# CH564 register map
Vendor: WCH Ltd.; File version: 1.0
Registers are 8-bit, read-write, reset 0x0 unless marked. A register's access mark holds for its fields unless they carry their own. Offsets are from the block's base; [hi:lo] are bit positions; {n}, {i} and the like mark numbered series.

## SYS
Base 0x40400000
0x00 R8_SAFE_ACCESS_SIG wo — safe accessing sign register
0x02 R8_SAFE_ACCESS_ID ro reset 0x1 — safe accessing ID register
  [7:0] R8_SAFE_ACCESS_ID — safe accessing ID
0x03 R8_WDOG_CLEAR wo — watch-dog clear register
  [7:0] R8_WDOG_CLEAR — watch-dog clear
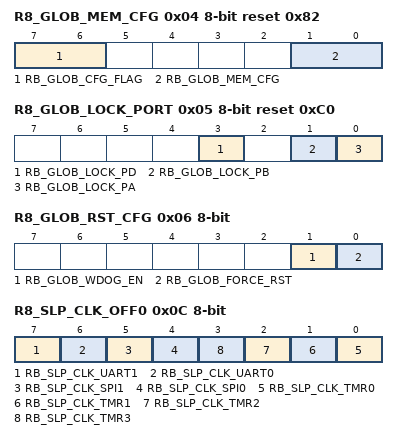
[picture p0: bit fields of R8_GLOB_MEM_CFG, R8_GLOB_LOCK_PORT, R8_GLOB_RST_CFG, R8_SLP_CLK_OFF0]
0x04 R8_GLOB_MEM_CFG access per field reset 0x82 — Memory configuration register
  [7:6] RB_GLOB_CFG_FLAG ro — Memory configuration flag
  [1:0] RB_GLOB_MEM_CFG rw — Memory configuration
0x05 R8_GLOB_LOCK_PORT reset 0xC0 — Global port lock configuration register
  [3] RB_GLOB_LOCK_PD — PD port lock configuration
  [1] RB_GLOB_LOCK_PB — PB port lock configuration
  [0] RB_GLOB_LOCK_PA — PA port lock configuration
0x06 R8_GLOB_RST_CFG access per field — Globally reset the configuration register
  [1] RB_GLOB_WDOG_EN rw — enable watch-dog reset
  [0] RB_GLOB_FORCE_RST wo — global software reset
0x07 R8_GLOB_RESET_KEEP — value keeper during global reset
0x09 R8_PLL_OUT_DIV reset 0x94 — output clock divider from PLL
  [7:4] RB_PLL_SYS_DIV — System clock division factor
0x0C R8_SLP_CLK_OFF0 — sleep clock off control byte 0
  [7] RB_SLP_CLK_UART1 — sleep UART1 clock
  [6] RB_SLP_CLK_UART0 — sleep UART0 clock
  [5] RB_SLP_CLK_SPI1 — sleep SPI1 clock
  [4] RB_SLP_CLK_SPI0 — sleep SPI0 clock
  [n] RB_SLP_CLK_TMR{n} (n=0..3) — sleep TMR{n} clock
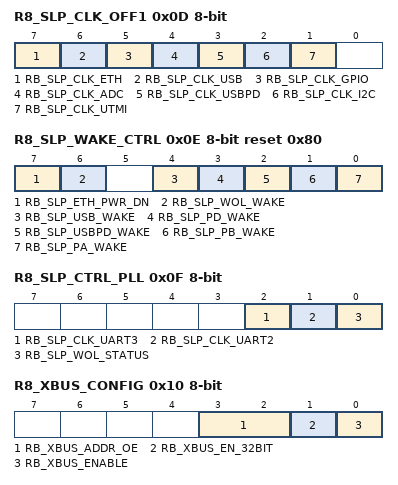
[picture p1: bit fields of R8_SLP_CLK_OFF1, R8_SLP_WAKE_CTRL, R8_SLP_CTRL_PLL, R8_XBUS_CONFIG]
0x0D R8_SLP_CLK_OFF1 — sleep clock off control byte 1
  [7] RB_SLP_CLK_ETH — sleep Ethernet clock
  [6] RB_SLP_CLK_USB — sleep USB clock
  [5] RB_SLP_CLK_GPIO — sleep GPIO clock
  [4] RB_SLP_CLK_ADC — sleep ADC clock
  [3] RB_SLP_CLK_USBPD — sleep USBPD clock
  [2] RB_SLP_CLK_I2C — sleep I2C clock
  [1] RB_SLP_CLK_UTMI — sleep UTMI clock
0x0E R8_SLP_WAKE_CTRL reset 0x80 — wake control
  [7] RB_SLP_ETH_PWR_DN — Ethernet module power control
  [6] RB_SLP_WOL_WAKE — enable Ethernet WOL waking
  [4] RB_SLP_USB_WAKE — enable USB waking
  [3] RB_SLP_PD_WAKE — enable PD waking
  [2] RB_SLP_USBPD_WAKE — enable USBPD waking
  [1] RB_SLP_PB_WAKE — enable PB waking
  [0] RB_SLP_PA_WAKE — enable PA waking
0x0F R8_SLP_CTRL_PLL access per field — PLL SLEEP control
  [2] RB_SLP_CLK_UART3 rw — sleep UART3 clock
  [1] RB_SLP_CLK_UART2 rw — sleep UART2 clock
  [0] RB_SLP_WOL_STATUS ro — Current ethernet WOL remote wake-up signal status
0x10 R8_XBUS_CONFIG — external bus configuration
  [3:2] RB_XBUS_ADDR_OE — external bus address output enable
  [1] RB_XBUS_EN_32BIT — external bus data control enable
  [0] RB_XBUS_ENABLE — external bus enable
0x12 R8_XBUS_CYCLE reset 0x4 — external bus read/write cyccles register
  [4:0] RB_XBUS_CYCLE — external bus read/write cyccles
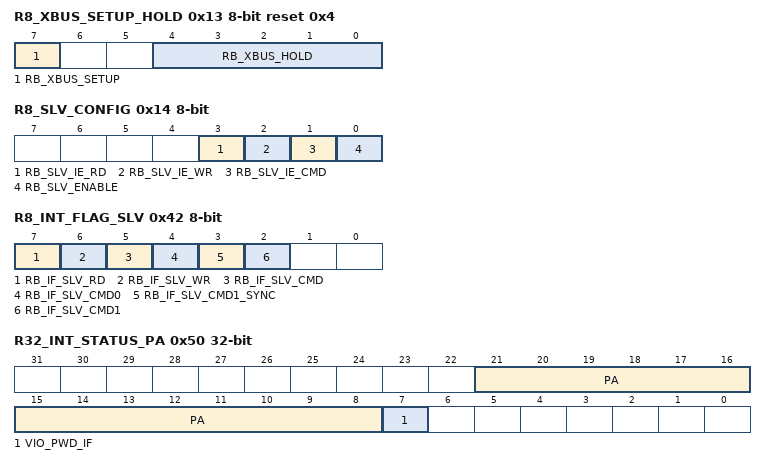
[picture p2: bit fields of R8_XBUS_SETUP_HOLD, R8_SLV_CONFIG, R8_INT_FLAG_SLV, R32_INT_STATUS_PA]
0x13 R8_XBUS_SETUP_HOLD reset 0x4 — external bus holdtime setting register
  [7] RB_XBUS_SETUP — The address of the external bus and the creation time of the data
  [4:0] RB_XBUS_HOLD — Number of external bus read/write signal end point clock
0x14 R8_SLV_CONFIG — SLV configuration register
  [3] RB_SLV_IE_RD — Data read the interrupt enable bit
  [2] RB_SLV_IE_WR — Data writes the interrupt enable bit
  [1] RB_SLV_IE_CMD — The command writes the interrupt enable bit
  [0] RB_SLV_ENABLE — SLV enable bit
0x16 R8_SLV_DOUT — SLV data output register
  [7:0] SLV_DOUT — SLV data output
0x17 R8_SLV_STATUS — SLV status output register
  [7:0] SLV_STATUS — SLV status output
0x42 R8_INT_FLAG_SLV access per field — SLV interrupt flag register
  [7] RB_IF_SLV_RD rw — SLV data output interrupt flag bit
  [6] RB_IF_SLV_WR rw — SLV data input interrupt flag bit
  [5] RB_IF_SLV_CMD ro — The synchronized SLV command input flag bits
  [4] RB_IF_SLV_CMD0 ro — The original SLV command input flag bit
  [3] RB_IF_SLV_CMD1_SYNC ro — The status of the SLV address line 1 after synchronization
  [2] RB_IF_SLV_CMD1 ro — The state of the original SLV address line 1
0x43 R8_INT_SLV_DIN ro — SLV data input register
  [7:0] INT_SLV_DIN — SLV data input
0x50 R32_INT_STATUS_PA 32-bit — The interrupt status register at the PA port
  [21:8] PA — The interrupt status bit of the PA port
  [7] VIO_PWD_IF — VIO power down interrupt flag bit
0x54 R32_INT_ENABLE_PA 32-bit — The interrupt enable register at the PA port
  [21:8] PA — The interrupt enable bit of the PA port
0x58 R32_INT_MODE_PA 32-bit — The interrupt mode register at the PA port
  [21:8] PA — The interrupt mode bit of the PA port
0x5C R32_INT_POLAR_PA 32-bit — The interrupt polar register at the PA port
  [21:8] PA — The interrupt polar bit of the PA port
0x60 R32_INT_STATUS_PB 32-bit — The interrupt status register at the PB port
  [22:0] PB — The interrupt status bit of the PB port
0x64 R32_INT_ENABLE_PB 32-bit — The interrupt enable register at the PB port
  [22:0] PB — The interrupt enable bit of the PB port
0x68 R32_INT_MODE_PB 32-bit — The interrupt mode register at the PB port
  [22:0] PB — The interrupt mode bit of the PB port
0x6C R32_INT_POLAR_PB 32-bit — The interrupt polar register at the PB port
  [22:0] PB — The interrupt polar bit of the PB port
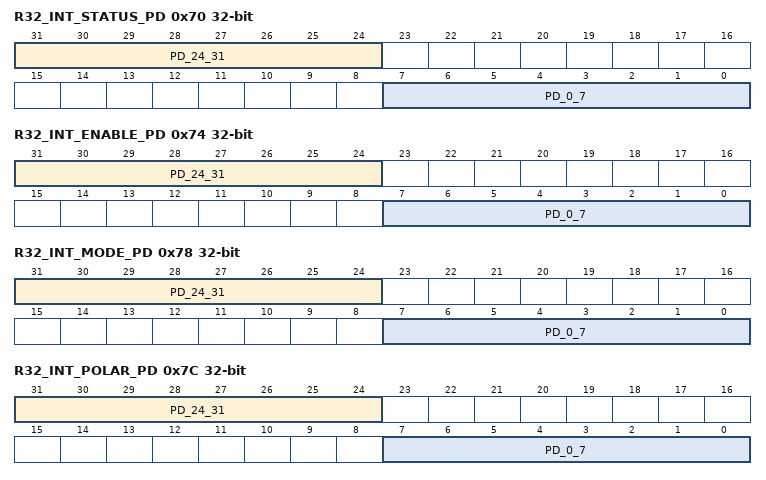
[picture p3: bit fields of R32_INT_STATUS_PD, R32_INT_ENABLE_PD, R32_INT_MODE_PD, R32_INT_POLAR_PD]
0x70 R32_INT_STATUS_PD 32-bit — The interrupt status register at the PA port
  [31:24] PD_24_31 — The interrupt status bit of the PD port
  [7:0] PD_0_7 — The interrupt status bit of the PD port
0x74 R32_INT_ENABLE_PD 32-bit — The interrupt enable register at the PD port
  [31:24] PD_24_31 — The interrupt enable bit of the PD port
  [7:0] PD_0_7 — The interrupt enable bit of the PD port
0x78 R32_INT_MODE_PD 32-bit — The interrupt mode register at the PD port
  [31:24] PD_24_31 — The interrupt mode bit of the PD port
  [7:0] PD_0_7 — The interrupt mode bit of the PD port
0x7C R32_INT_POLAR_PD 32-bit — The interrupt polar register at the PD port
  [31:24] PD_24_31 — The interrupt polar bit of the PD port
  [7:0] PD_0_7 — The interrupt polar bit of the PD port
0x80 R32_PA_DIR 32-bit — GPIO PA I/O direction
  [21:0] PA_DIR
0x84 R32_PA_PIN 32-bit ro — GPIO PA input
  [21:0] PA_PIN
0x88 R32_PA_OUT 32-bit — GPIO PA output
  [21:0] PA_OUT
0x8C R32_PA_CLR 32-bit ro — GPIO PA clear output
  [21:0] PA_CLR
0x90 R32_PA_PU 32-bit — GPIO PA pullup resistance enable
  [21:0] PA_PU
0x94 R32_PA_PD 32-bit — GPIO PA output open-drain_input pulldown resistance enable
  [21:0] PA_PD
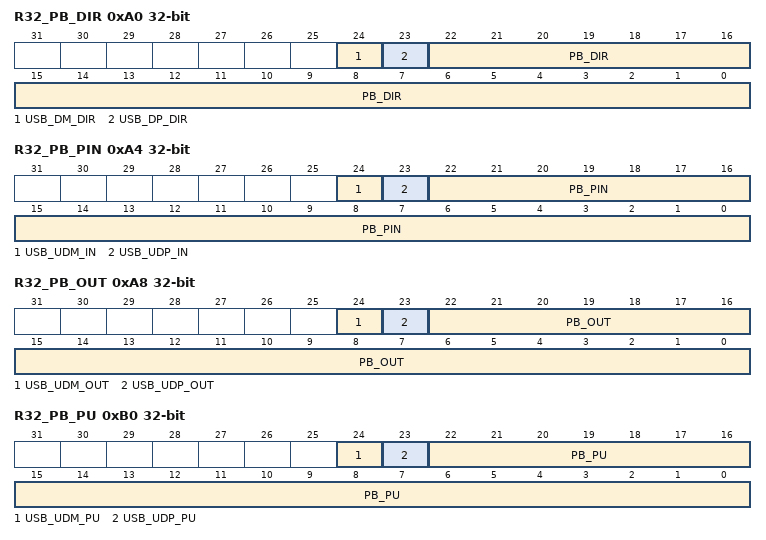
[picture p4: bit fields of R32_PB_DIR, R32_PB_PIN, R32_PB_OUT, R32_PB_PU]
0xA0 R32_PB_DIR 32-bit — GPIO PB I/O direction
  [24] USB_DM_DIR — Pin current intput/output direction control domain
  [23] USB_DP_DIR — Pin current intput/output direction control domain
  [22:0] PB_DIR — GPIO PB I/O direction
0xA4 R32_PB_PIN 32-bit ro — GPIO PB input
  [24] USB_UDM_IN — Pin intput level status
  [23] USB_UDP_IN — Pin intput level status
  [22:0] PB_PIN — GPIO PB input level status
0xA8 R32_PB_OUT 32-bit — GPIO PB output
  [24] USB_UDM_OUT — Pin output level status
  [23] USB_UDP_OUT — Pin output level status
  [22:0] PB_OUT — GPIO PB output level status
0xAC R32_PB_CLR 32-bit ro — GPIO PB clear output
  [22:0] PB_CLR
0xB0 R32_PB_PU 32-bit — GPIO PB pullup resistance enable
  [24] USB_UDM_PU — Pin pull-up function enable /close control bit
  [23] USB_UDP_PU — Pin pull-up function enable /close control bit
  [22:0] PB_PU — GPIO PB pull-up resistance enable
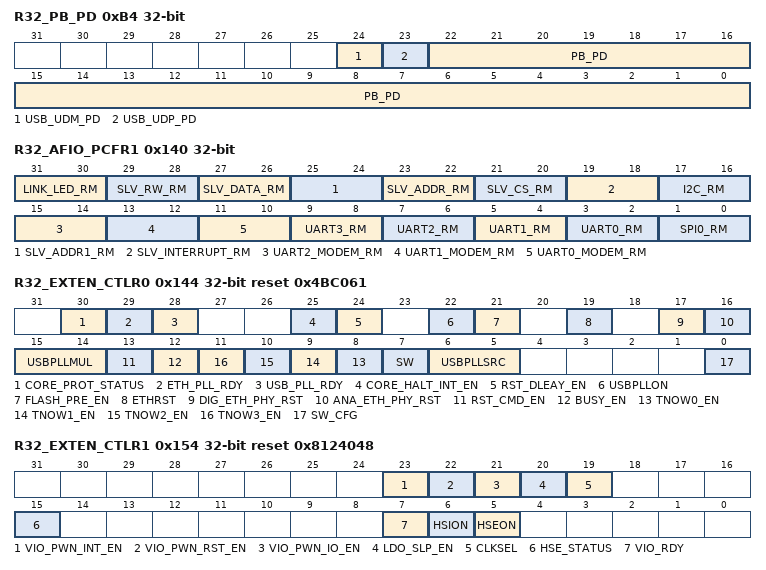
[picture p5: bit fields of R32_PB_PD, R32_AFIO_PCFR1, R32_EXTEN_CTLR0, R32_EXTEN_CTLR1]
0xB4 R32_PB_PD 32-bit — GPIO PB output open-drain_input pulldown resistance enable
  [24] USB_UDM_PD — Pin function enable /close control bit
  [23] USB_UDP_PD — Pin function enable /close control bit
  [22:0] PB_PD — GPIO PB output open-drain_input pulldown resistance enable
0xC0 R32_PD_DIR 32-bit — GPIO PD I/O direction
  [31:0] PD_DIR
0xC4 R32_PD_PIN 32-bit ro — GPIO PD input
  [31:0] PD_PIN
0xC8 R32_PD_OUT 32-bit — GPIO PD output
  [31:0] PD_OUT
0xD0 R32_PD_PU 32-bit — GPIO PD pullup resistance enable
  [31:0] PD_PU
0xD4 R32_PD_PD 32-bit — GPIO PD output open-drain_input pulldown resistance enable
  [31:0] PD_PD
0x140 R32_AFIO_PCFR1 32-bit — AF remap and debug I/O configuration register (AFIO_PCFR1)
  [31:30] LINK_LED_RM — LINK LED remapping
  [29:28] SLV_RW_RM — SLV remapping
  [27:26] SLV_DATA_RM — SLV data remapping
  [25:24] SLV_ADDR1_RM — SLV address1 remapping
  [23:22] SLV_ADDR_RM — SLV command data selection input pin remapping
  [21:20] SLV_CS_RM — SLV piece selection pin remapping
  [19:18] SLV_INTERRUPT_RM — SLV interrupt pin remapping
  [17:16] I2C_RM — I2C remapping
  [15:14] UART2_MODEM_RM — UART2 MODEM remapping
  [13:12] UART1_MODEM_RM — UART1 MODEM remapping
  [11:10] UART0_MODEM_RM — UART0 MODEM remapping
  [2n+3:2n+2] UART{n}_RM (n=0..3) — UART{n} remapping
  [1:0] SPI0_RM — SPI0 remapping
0x144 R32_EXTEN_CTLR0 32-bit access per field reset 0x4BC061 — Configure the extended control register 0
  [30] CORE_PROT_STATUS ro — Core protected moed status bit
  [29] ETH_PLL_RDY ro — ETH PLL ready flag bit
  [28] USB_PLL_RDY ro — USB PLL ready flag bit
  [25] CORE_HALT_INT_EN rw — Kernel error interrupt enabled
  [24] RST_DLEAY_EN rw — reset time extension control bit
  [22] USBPLLON rw — USBPLL clock enable bit
  [21] FLASH_PRE_EN rw — flash clock pre-divisor enable
  [19] ETHRST rw — ethernet reset control
  [17] DIG_ETH_PHY_RST rw — ethernet phy digital module reset control
  [16] ANA_ETH_PHY_RST rw — ethernet phy analog module reset control
  [15:14] USBPLLMUL rw — USBPLL input clock frequency multiplication factor
  [13] RST_CMD_EN rw — global reset enabled
  [12] BUSY_EN rw — the busy signal output of spi and slv enabled
  [n+8] TNOW{n}_EN rw (n=0..3) — the TNOW signal output of the UART{n} is enabled
  [7] SW rw — select the systemitem clock source
  [6:5] USBPLLSRC rw — USBPLL reference clock source
  [0] SW_CFG rw — Serial wire JTAG configuration
0x154 R32_EXTEN_CTLR1 32-bit access per field reset 0x8124048 — Configure the extended control register 1
  [23] VIO_PWN_INT_EN rw — Enables an outage when the VIO power is down
  [22] VIO_PWN_RST_EN rw — Enable system reset when the VIO power is down
  [21] VIO_PWN_IO_EN rw — Enable the IO port of the peripheral to input a high level when the VIO power is down
  [20] LDO_SLP_EN rw — Enable the LDO to go into sleep mode when the VIO power is down
  [19] CLKSEL rw — Clock signal selection
  [15] HSE_STATUS ro — External crystal current level status
  [7] VIO_RDY ro — VIO status
  [6] HSION rw — Internal High Speed clock enable
  [5] HSEON rw — External High Speed clock enable
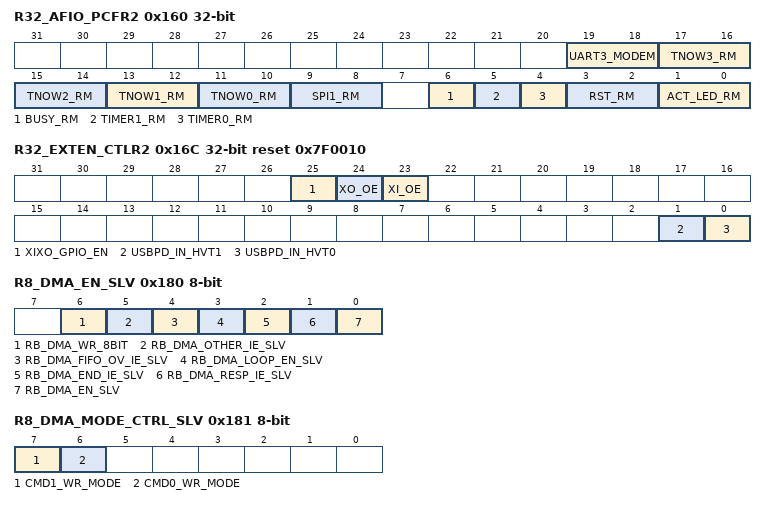
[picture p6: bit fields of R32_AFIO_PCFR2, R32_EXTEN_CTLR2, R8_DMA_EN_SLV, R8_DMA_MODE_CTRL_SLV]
0x160 R32_AFIO_PCFR2 32-bit — AF remap and debug I/O configuration register (AFIO_PCFR2)
  [19:18] UART3_MODEM — UART3 MODEM remapping
  [2n+11:2n+10] TNOW{n}_RM (n=0..3) — TNOW{n} remapping
  [9:8] SPI1_RM — UART3 remapping
  [6] BUSY_RM — BUSY remapping
  [5] TIMER1_RM — TIMER1 remapping
  [4] TIMER0_RM — TIMER0 remapping
  [3:2] RST_RM — reset pin remapping
  [1:0] ACT_LED_RM — active led remapping
0x16C R32_EXTEN_CTLR2 32-bit reset 0x7F0010 — Configure the extended control register 2
  [25] XIXO_GPIO_EN — XI/XO pin open-drain_ouput control bit
  [24] XO_OE — XO ouput enable bit
  [23] XI_OE — XI ouput enable bit
  [1] USBPD_IN_HVT1 — PD PIN PB19 high threshold input mode
  [0] USBPD_IN_HVT0 — PD PIN PB18 high threshold input mode
0x16E R8_ADC_GPIO_MODE reset 0x7F — ADC port mode configuration register
  [6:0] ADC_GPIO_MODE — ADC external channel input mode selection
0x180 R8_DMA_EN_SLV — SLV DMA enable register
  [6] RB_DMA_WR_8BIT — selection of transfer data length for DMA write operations
  [5] RB_DMA_OTHER_IE_SLV — when in compatibility mode, Transmission of non-DMA data state interrupts the enable bit
  [4] RB_DMA_FIFO_OV_IE_SLV — The FIFO full state interrupts the enable bit
  [3] RB_DMA_LOOP_EN_SLV — SLV DMA cyclic address mode control bits
  [2] RB_DMA_END_IE_SLV — SLV DMA error transmission end enable control bit
  [1] RB_DMA_RESP_IE_SLV — SLV DMA error transmission interrupts enable control bit
  [0] RB_DMA_EN_SLV — SLV DMA mode enable control bit
0x181 R8_DMA_MODE_CTRL_SLV — SLV DMA mode control register
  [7] CMD1_WR_MODE — DMA transfer command word 1 read and write type
  [6] CMD0_WR_MODE — DMA transfer command word 0 read and write type
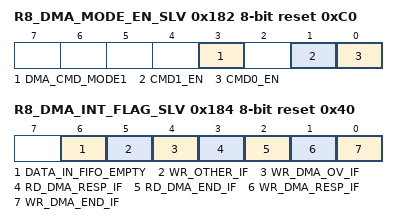
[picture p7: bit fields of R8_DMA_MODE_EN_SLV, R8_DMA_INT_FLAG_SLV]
0x182 R8_DMA_MODE_EN_SLV reset 0xC0 — SLV DMA mode enable register
  [3] DMA_CMD_MODE1 — DMA transfer command word mode1
  [1] CMD1_EN — DMA transfer command word 1 control bit
  [0] CMD0_EN — DMA transfer command word 0 control bit
0x184 R8_DMA_INT_FLAG_SLV reset 0x40 — SLV DMA interrupt flag register
  [6] DATA_IN_FIFO_EMPTY — Whether DATA_IN_FIFO is empty
  [5] WR_OTHER_IF — data are written to the flag bit
  [4] WR_DMA_OV_IF — input FIFO full flag
  [3] RD_DMA_RESP_IF — DMA occurrence mode transmission error flag bit
  [2] RD_DMA_END_IF — DMA occurrence mode transmission end flag bit
  [1] WR_DMA_RESP_IF — DMA receive mode transmission error flag bit
  [0] WR_DMA_END_IF — DMA receive mode transmission end flag bit
0x188 R32_WR_DMA_START_ADDR_SLV 32-bit — DMA receive mode start address register
  [17:0] WR_DMA_START_ADDR_SLV — DMA receive mode start address
0x18C R32_WR_DMA_END_ADDR_SLV 32-bit reset 0x3FFFF — DMA receive mode end address register
  [17:0] WR_DMA_START_ADDR_SLV — DMA receive mode end address
0x194 R32_RD_DMA_START_ADDR_SLV 32-bit — DMA send mode start address register
  [17:0] RD_DMA_START_ADDR_SLV — DMA send mode start address
0x198 R32_RD_DMA_END_ADDR_SLV 32-bit reset 0x3FFFF — DMA send mode end address register
  [17:0] RD_DMA_START_ADDR_SLV — DMA send mode end address
0x19C R32_DMA_END_NOW_SLV 32-bit ro — DMA current address register
  [17:0] DMA_NOW_ADDR_SLV — DMA current address
0x1A0 R8_DMA_CMD0_SLV — DMA mode command word0 register
  [7:0] DMA_CMD0_SLV — command word required to start DMA mode
0x1A1 R8_DMA_CMD1_SLV — DMA mode command word1 register
  [7:0] DMA_CMD1_SLV — command word required to start DMA mode
0x1A4 R8_SLV_RESET_CMD reset 0x5 — DMA reset the command word register
  [7:0] SLV_RESET_CMD — A global reset is generated upon receipt of this command
0x1A5 R8_SLV_BUSY — SLV busy flag register
  [0] SLV_BUSY — SLV busy flag
0x1B0 R8_OTHER_DATA ro — Non-DMA writes to the data register
  [7:0] OTHER_DATA — Non-DMA writes to the data
0x1B4 R16_DMA_DEC_LEN 16-bit ro — DMA parses length register
  [15:0] DMA_DEC_LEN — parse the resulting DMA length
0x1B6 R16_DMA_DEC_OFFSET 16-bit ro — DMA resolves the offset address register
  [15:0] DMA_DEC_OFFSET — Resolved DMA address offset
